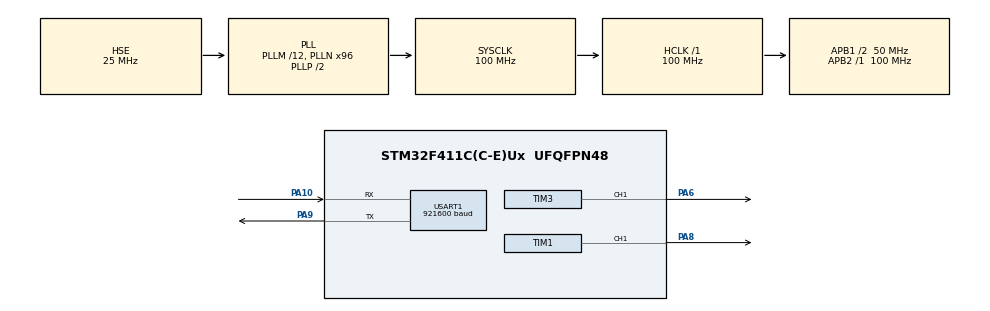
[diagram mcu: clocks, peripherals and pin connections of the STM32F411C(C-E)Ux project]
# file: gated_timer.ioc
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Dma.Request0=TIM3_CH1/TRIG
Dma.TIM3_CH1/TRIG.0.Direction=DMA_MEMORY_TO_PERIPH
Dma.TIM3_CH1/TRIG.0.FIFOMode=DMA_FIFOMODE_DISABLE
Dma.TIM3_CH1/TRIG.0.Instance=DMA1_Stream4
Dma.TIM3_CH1/TRIG.0.MemDataAlignment=DMA_MDATAALIGN_HALFWORD
Dma.TIM3_CH1/TRIG.0.MemInc=DMA_MINC_ENABLE
Dma.TIM3_CH1/TRIG.0.Mode=DMA_CIRCULAR
Dma.TIM3_CH1/TRIG.0.PeriphDataAlignment=DMA_PDATAALIGN_HALFWORD
Dma.TIM3_CH1/TRIG.0.PeriphInc=DMA_PINC_DISABLE
Dma.TIM3_CH1/TRIG.0.Priority=DMA_PRIORITY_LOW
Mcu.Family=STM32F4
Mcu.Name=STM32F411C(C-E)Ux
Mcu.Package=UFQFPN48
NVIC.DMA1_Stream4_IRQn=true\:0\:0\:false\:false\:true\:false\:true\:true
NVIC.PriorityGroup=NVIC_PRIORITYGROUP_4
PA10.Mode=Asynchronous
PA10.Signal=USART1_RX
PA6.Signal=S_TIM3_CH1
PA8.Signal=S_TIM1_CH1
PA9.Mode=Asynchronous
PA9.Signal=USART1_TX
PH0\ -\ OSC_IN.Mode=HSE-External-Oscillator
PH0\ -\ OSC_IN.Signal=RCC_OSC_IN
PH1\ -\ OSC_OUT.Mode=HSE-External-Oscillator
PH1\ -\ OSC_OUT.Signal=RCC_OSC_OUT
ProjectManager.HeapSize=0x200
ProjectManager.StackSize=0x400
ProjectManager.TargetToolchain=STM32CubeIDE
RCC.48MHZClocksFreq_Value=50000000
RCC.AHBFreq_Value=100000000
RCC.APB1CLKDivider=RCC_HCLK_DIV2
RCC.APB1Freq_Value=50000000
RCC.APB1TimFreq_Value=100000000
RCC.APB2Freq_Value=100000000
RCC.APB2TimFreq_Value=100000000
RCC.CortexFreq_Value=100000000
RCC.HCLKFreq_Value=100000000
RCC.HSE_VALUE=25000000
RCC.HSI_VALUE=16000000
RCC.LSE_VALUE=32768
RCC.PLLM=12
RCC.PLLN=96
RCC.PLLSourceVirtual=RCC_PLLSOURCE_HSE
RCC.SYSCLKFreq_VALUE=100000000
RCC.SYSCLKSource=RCC_SYSCLKSOURCE_PLLCLK
RCC.VCOOutputFreq_Value=200000000
SH.S_TIM1_CH1.0=TIM1_CH1,PWM Generation1 CH1
SH.S_TIM3_CH1.0=TIM3_CH1,PWM Generation1 CH1
TIM1.Channel-PWM\ Generation1\ CH1=TIM_CHANNEL_1
TIM1.OCFastMode_PWM-PWM\ Generation1\ CH1=TIM_OCFAST_ENABLE
TIM1.Period=2600
TIM1.Prescaler=0
TIM1.Pulse-PWM\ Generation1\ CH1=1300
TIM3.Channel-PWM\ Generation1\ CH1=TIM_CHANNEL_1
TIM3.OCMode_PWM-PWM\ Generation1\ CH1=TIM_OCMODE_PWM1
TIM3.OCPolarity_1=TIM_OCPOLARITY_HIGH
TIM3.Period=255
TIM3.Prescaler=220
TIM3.Pulse-PWM\ Generation1\ CH1=130
TIM3.TIM_MasterOutputTrigger=TIM_TRGO_OC1REF
TIM3.TIM_MasterSlaveMode=TIM_MASTERSLAVEMODE_DISABLE
USART1.BaudRate=921600
USART1.VirtualMode=VM_ASYNC
VP_TIM1_VS_ClockSourceINT.Mode=Internal
VP_TIM1_VS_ClockSourceITR.Mode=TriggerSource_ITR2
VP_TIM1_VS_ControllerModeGated.Mode=Gated Mode
VP_TIM3_VS_ClockSourceINT.Mode=Internal
board=custom

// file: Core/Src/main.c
/* USER CODE BEGIN Header */
/**
  ******************************************************************************
  * @file           : main.c
  * @brief          : Main program body
  ******************************************************************************
  * @attention
  *
  * Copyright (c) 2023 STMicroelectronics.
  * All rights reserved.
  *
  * This software is licensed under terms that can be found in the LICENSE file
  * in the root directory of this software component.
  * If no LICENSE file comes with this software, it is provided AS-IS.
  *
  ******************************************************************************
  */
/* USER CODE END Header */
#include "main.h"

TIM_HandleTypeDef htim1;
TIM_HandleTypeDef htim3;
DMA_HandleTypeDef hdma_tim3_ch1_trig;

UART_HandleTypeDef huart1;

/* USER CODE BEGIN PV */
uint16_t pwm_buffer[2 * 33];
/* USER CODE END PV */

void SystemClock_Config(void);
static void MX_GPIO_Init(void);
static void MX_DMA_Init(void);
static void MX_USART1_UART_Init(void);
static void MX_TIM1_Init(void);
static void MX_TIM3_Init(void);

int main(void)
{

  /* MCU Configuration--------------------------------------------------------*/

  /* Reset of all peripherals, Initializes the Flash interface and the Systick. */
  HAL_Init();

  /* Configure the system clock */
  SystemClock_Config();

  /* Initialize all configured peripherals */
  MX_GPIO_Init();
  MX_DMA_Init();
  MX_USART1_UART_Init();
  MX_TIM1_Init();
  MX_TIM3_Init();
  /* USER CODE BEGIN 2 */

  HAL_TIM_PWM_Start(&htim1, TIM_CHANNEL_1);
  HAL_TIM_PWM_Start(&htim3, TIM_CHANNEL_1);
  //HAL_TIM_PWM_Start_DMA(&htim3, TIM_CHANNEL_1, pData, Length)

  /* USER CODE END 2 */

  /* Infinite loop */
  while (1)
  {

  }
}

void SystemClock_Config(void)
{
  RCC_OscInitTypeDef RCC_OscInitStruct = {0};
  RCC_ClkInitTypeDef RCC_ClkInitStruct = {0};

  /** Configure the main internal regulator output voltage
  */
  __HAL_RCC_PWR_CLK_ENABLE();
  __HAL_PWR_VOLTAGESCALING_CONFIG(PWR_REGULATOR_VOLTAGE_SCALE1);

  /** Initializes the RCC Oscillators according to the specified parameters
  * in the RCC_OscInitTypeDef structure.
  */
  RCC_OscInitStruct.OscillatorType = RCC_OSCILLATORTYPE_HSE;
  RCC_OscInitStruct.HSEState = RCC_HSE_ON;
  RCC_OscInitStruct.PLL.PLLState = RCC_PLL_ON;
  RCC_OscInitStruct.PLL.PLLSource = RCC_PLLSOURCE_HSE;
  RCC_OscInitStruct.PLL.PLLM = 12;
  RCC_OscInitStruct.PLL.PLLN = 96;
  RCC_OscInitStruct.PLL.PLLP = RCC_PLLP_DIV2;
  RCC_OscInitStruct.PLL.PLLQ = 4;
  if (HAL_RCC_OscConfig(&RCC_OscInitStruct) != HAL_OK)
  {
    Error_Handler();
  }

  /** Initializes the CPU, AHB and APB buses clocks
  */
  RCC_ClkInitStruct.ClockType = RCC_CLOCKTYPE_HCLK|RCC_CLOCKTYPE_SYSCLK
                              |RCC_CLOCKTYPE_PCLK1|RCC_CLOCKTYPE_PCLK2;
  RCC_ClkInitStruct.SYSCLKSource = RCC_SYSCLKSOURCE_PLLCLK;
  RCC_ClkInitStruct.AHBCLKDivider = RCC_SYSCLK_DIV1;
  RCC_ClkInitStruct.APB1CLKDivider = RCC_HCLK_DIV2;
  RCC_ClkInitStruct.APB2CLKDivider = RCC_HCLK_DIV1;

  if (HAL_RCC_ClockConfig(&RCC_ClkInitStruct, FLASH_LATENCY_3) != HAL_OK)
  {
    Error_Handler();
  }
}

static void MX_TIM1_Init(void)
{

  TIM_ClockConfigTypeDef sClockSourceConfig = {0};
  TIM_SlaveConfigTypeDef sSlaveConfig = {0};
  TIM_MasterConfigTypeDef sMasterConfig = {0};
  TIM_OC_InitTypeDef sConfigOC = {0};
  TIM_BreakDeadTimeConfigTypeDef sBreakDeadTimeConfig = {0};

  htim1.Instance = TIM1;
  htim1.Init.Prescaler = 0;
  htim1.Init.CounterMode = TIM_COUNTERMODE_UP;
  htim1.Init.Period = 2600;
  htim1.Init.ClockDivision = TIM_CLOCKDIVISION_DIV1;
  htim1.Init.RepetitionCounter = 0;
  htim1.Init.AutoReloadPreload = TIM_AUTORELOAD_PRELOAD_DISABLE;
  if (HAL_TIM_Base_Init(&htim1) != HAL_OK)
  {
    Error_Handler();
  }
  sClockSourceConfig.ClockSource = TIM_CLOCKSOURCE_INTERNAL;
  if (HAL_TIM_ConfigClockSource(&htim1, &sClockSourceConfig) != HAL_OK)
  {
    Error_Handler();
  }
  if (HAL_TIM_PWM_Init(&htim1) != HAL_OK)
  {
    Error_Handler();
  }
  sSlaveConfig.SlaveMode = TIM_SLAVEMODE_GATED;
  sSlaveConfig.InputTrigger = TIM_TS_ITR2;
  if (HAL_TIM_SlaveConfigSynchro(&htim1, &sSlaveConfig) != HAL_OK)
  {
    Error_Handler();
  }
  sMasterConfig.MasterOutputTrigger = TIM_TRGO_RESET;
  sMasterConfig.MasterSlaveMode = TIM_MASTERSLAVEMODE_DISABLE;
  if (HAL_TIMEx_MasterConfigSynchronization(&htim1, &sMasterConfig) != HAL_OK)
  {
    Error_Handler();
  }
  sConfigOC.OCMode = TIM_OCMODE_PWM1;
  sConfigOC.Pulse = 1300;
  sConfigOC.OCPolarity = TIM_OCPOLARITY_HIGH;
  sConfigOC.OCNPolarity = TIM_OCNPOLARITY_HIGH;
  sConfigOC.OCFastMode = TIM_OCFAST_ENABLE;
  sConfigOC.OCIdleState = TIM_OCIDLESTATE_RESET;
  sConfigOC.OCNIdleState = TIM_OCNIDLESTATE_RESET;
  if (HAL_TIM_PWM_ConfigChannel(&htim1, &sConfigOC, TIM_CHANNEL_1) != HAL_OK)
  {
    Error_Handler();
  }
  sBreakDeadTimeConfig.OffStateRunMode = TIM_OSSR_DISABLE;
  sBreakDeadTimeConfig.OffStateIDLEMode = TIM_OSSI_DISABLE;
  sBreakDeadTimeConfig.LockLevel = TIM_LOCKLEVEL_OFF;
  sBreakDeadTimeConfig.DeadTime = 0;
  sBreakDeadTimeConfig.BreakState = TIM_BREAK_DISABLE;
  sBreakDeadTimeConfig.BreakPolarity = TIM_BREAKPOLARITY_HIGH;
  sBreakDeadTimeConfig.AutomaticOutput = TIM_AUTOMATICOUTPUT_DISABLE;
  if (HAL_TIMEx_ConfigBreakDeadTime(&htim1, &sBreakDeadTimeConfig) != HAL_OK)
  {
    Error_Handler();
  }
  HAL_TIM_MspPostInit(&htim1);

}

static void MX_TIM3_Init(void)
{

  TIM_ClockConfigTypeDef sClockSourceConfig = {0};
  TIM_MasterConfigTypeDef sMasterConfig = {0};
  TIM_OC_InitTypeDef sConfigOC = {0};

  htim3.Instance = TIM3;
  htim3.Init.Prescaler = 220;
  htim3.Init.CounterMode = TIM_COUNTERMODE_UP;
  htim3.Init.Period = 255;
  htim3.Init.ClockDivision = TIM_CLOCKDIVISION_DIV1;
  htim3.Init.AutoReloadPreload = TIM_AUTORELOAD_PRELOAD_DISABLE;
  if (HAL_TIM_Base_Init(&htim3) != HAL_OK)
  {
    Error_Handler();
  }
  sClockSourceConfig.ClockSource = TIM_CLOCKSOURCE_INTERNAL;
  if (HAL_TIM_ConfigClockSource(&htim3, &sClockSourceConfig) != HAL_OK)
  {
    Error_Handler();
  }
  if (HAL_TIM_PWM_Init(&htim3) != HAL_OK)
  {
    Error_Handler();
  }
  sMasterConfig.MasterOutputTrigger = TIM_TRGO_OC1REF;
  sMasterConfig.MasterSlaveMode = TIM_MASTERSLAVEMODE_DISABLE;
  if (HAL_TIMEx_MasterConfigSynchronization(&htim3, &sMasterConfig) != HAL_OK)
  {
    Error_Handler();
  }
  sConfigOC.OCMode = TIM_OCMODE_PWM1;
  sConfigOC.Pulse = 130;
  sConfigOC.OCPolarity = TIM_OCPOLARITY_HIGH;
  sConfigOC.OCFastMode = TIM_OCFAST_DISABLE;
  if (HAL_TIM_PWM_ConfigChannel(&htim3, &sConfigOC, TIM_CHANNEL_1) != HAL_OK)
  {
    Error_Handler();
  }
  HAL_TIM_MspPostInit(&htim3);

}

static void MX_USART1_UART_Init(void)
{

  huart1.Instance = USART1;
  huart1.Init.BaudRate = 921600;
  huart1.Init.WordLength = UART_WORDLENGTH_8B;
  huart1.Init.StopBits = UART_STOPBITS_1;
  huart1.Init.Parity = UART_PARITY_NONE;
  huart1.Init.Mode = UART_MODE_TX_RX;
  huart1.Init.HwFlowCtl = UART_HWCONTROL_NONE;
  huart1.Init.OverSampling = UART_OVERSAMPLING_16;
  if (HAL_UART_Init(&huart1) != HAL_OK)
  {
    Error_Handler();
  }

}

static void MX_DMA_Init(void)
{

  /* DMA controller clock enable */
  __HAL_RCC_DMA1_CLK_ENABLE();

  /* DMA interrupt init */
  /* DMA1_Stream4_IRQn interrupt configuration */
  HAL_NVIC_SetPriority(DMA1_Stream4_IRQn, 0, 0);
  HAL_NVIC_EnableIRQ(DMA1_Stream4_IRQn);

}

static void MX_GPIO_Init(void)
{

  /* GPIO Ports Clock Enable */
  __HAL_RCC_GPIOH_CLK_ENABLE();
  __HAL_RCC_GPIOA_CLK_ENABLE();

}

void Error_Handler(void)
{
  __disable_irq();
  while (1)
  {
  }
}
